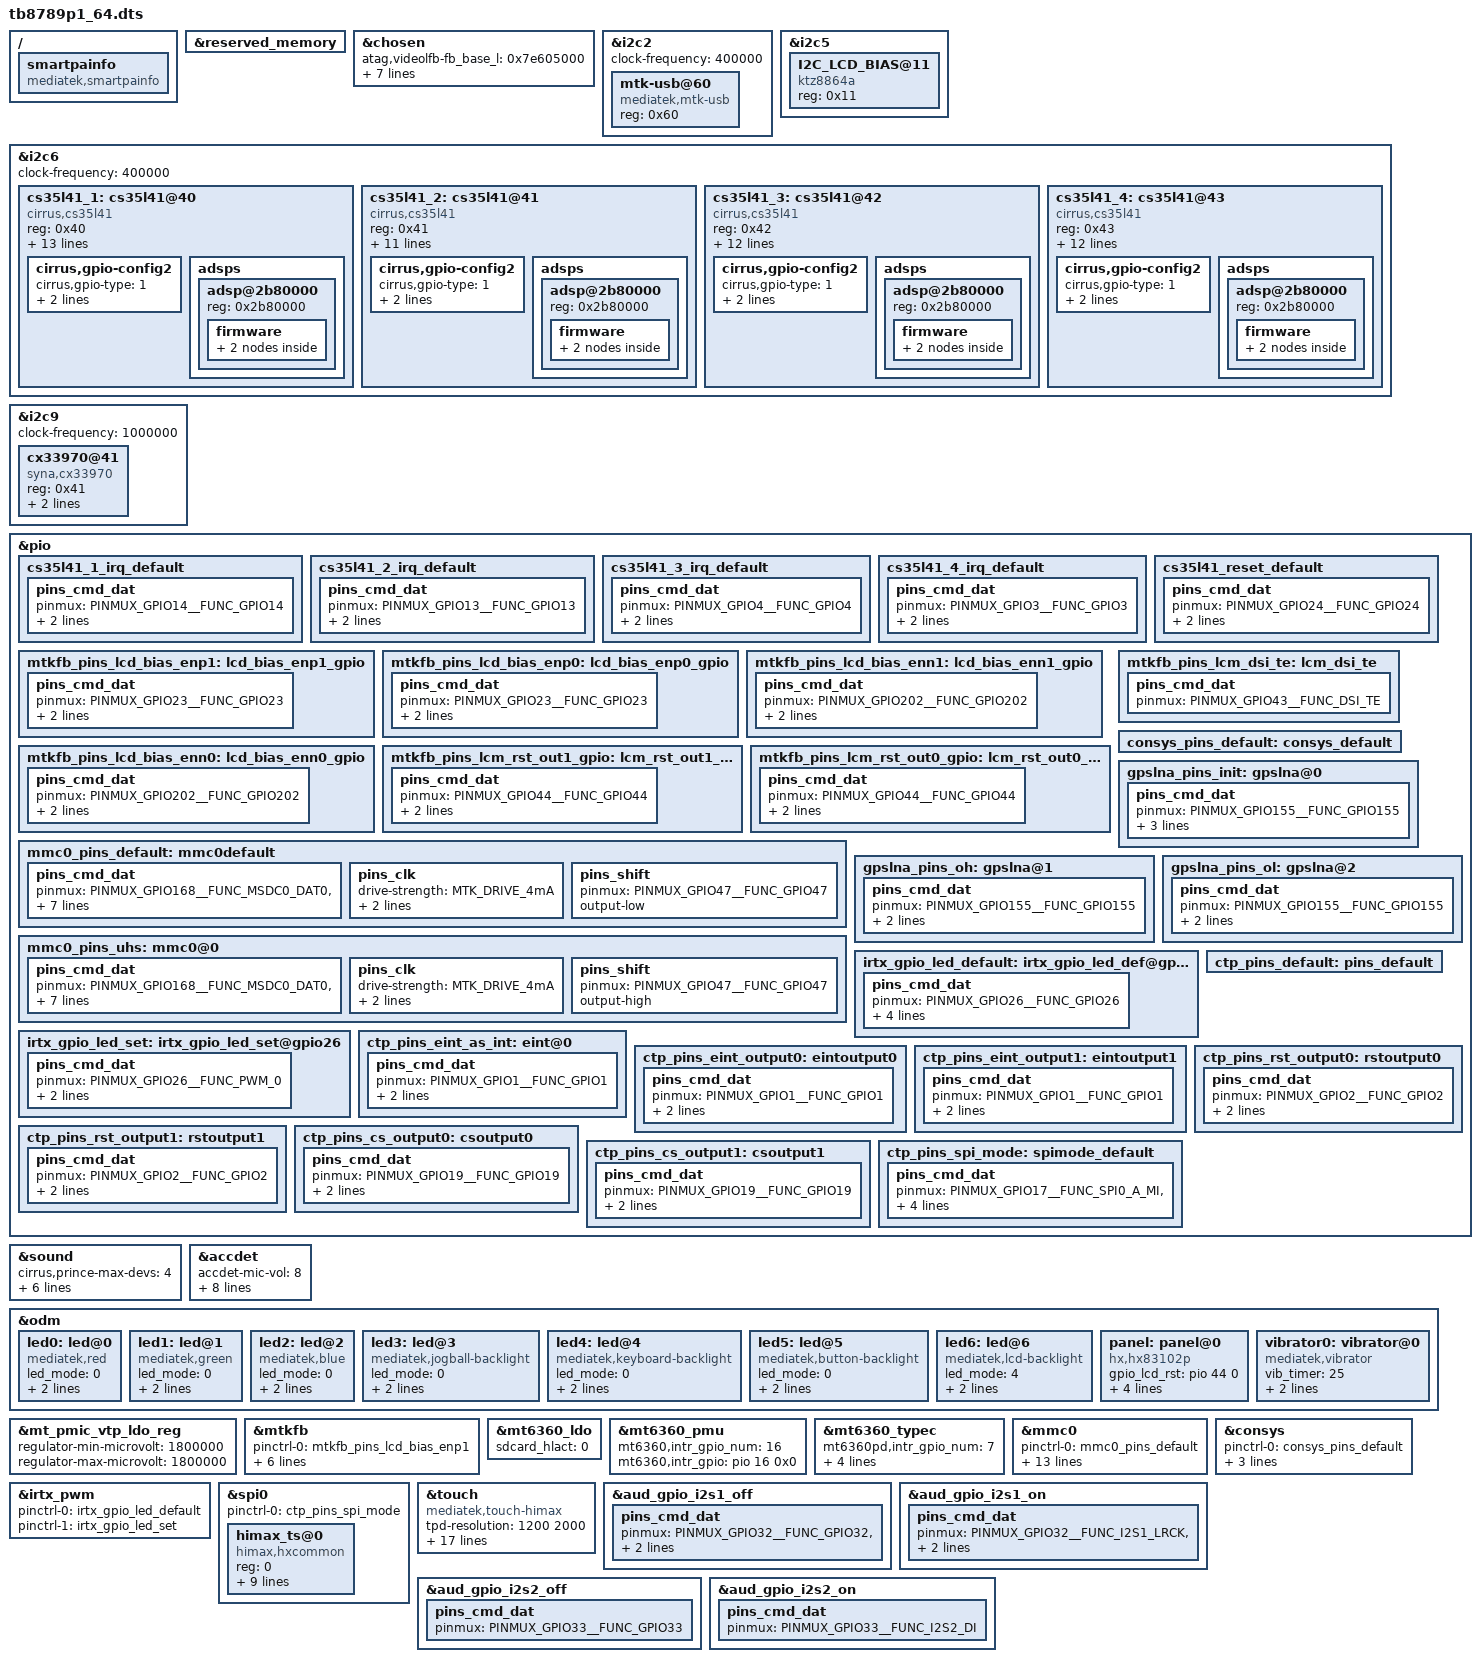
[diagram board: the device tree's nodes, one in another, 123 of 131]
/*
 * Copyright (C) 2015 MediaTek Inc.
 *
 * This program is free software: you can redistribute it and/or modify
 * it under the terms of the GNU General Public License version 2 as
 * published by the Free Software Foundation.
 *
 * This program is distributed in the hope that it will be useful,
 * but WITHOUT ANY WARRANTY; without even the implied warranty of
 * MERCHANTABILITY or FITNESS FOR A PARTICULAR PURPOSE. See the
 * GNU General Public License for more details.
 */
/dts-v1/;
/plugin/;
#include <dt-bindings/interrupt-controller/irq.h>
#include <dt-bindings/interrupt-controller/arm-gic.h>
#include <dt-bindings/pinctrl/mt6785-pinfunc.h>

/ {
	smartpainfo: smartpainfo {
		compatible = "mediatek,smartpainfo";
	};
};

&reserved_memory {
};

/* chosen */
&chosen {
	/* fpga may has no lk, we need to specify display info here */
	/* fb buffer is reserved using this dts by memory node above */

	atag,videolfb-fb_base_l = <0x7e605000>;
	atag,videolfb-fb_base_h = <0x0>;
	atag,videolfb-islcmfound = <1>;
	atag,videolfb-islcm_inited = <0>;
	atag,videolfb-fps= <6000>;
	atag,videolfb-vramSize= <0x017e8000>;
	atag,videolfb-lcmname=
		"hx83102p_wuxga2000_dsi_vdo_boe_drv";
};


&i2c2 {
	clock-frequency = <400000>;

	mtk-usb@60 {
		compatible = "mediatek,mtk-usb";
		reg = <0x60>;
		status = "okay";
	};
};

&i2c5 {
	I2C_LCD_BIAS@11 {
		compatible = "ktz8864a" ;
		reg = <0x11> ;
		status = "okay" ;
	};
};

&i2c6 {
	clock-frequency = <400000>;

	status="okay";

	/* Speaker 1st Amp */
	/*U2401  ---->  40*/
	cs35l41_1: cs35l41@40 {
		compatible = "cirrus,cs35l41";
		reg = <0x40>;

		reset-gpios = <&pio 24 0>;
		interrupt-parent = <&pio>;
		interrupts = <14 IRQ_TYPE_LEVEL_LOW 14 0>;
		interrupt-controller;
		#interrupt-cells = <2>;
		interrupt-names = "cs35l41_1_irq";

		pinctrl-names="default";
		pinctrl-0=<&cs35l41_1_irq_default>, <&cs35l41_reset_default>;


		cirrus,boost-peak-milliamp = <4500>;
		cirrus,boost-ind-nanohenry = <1000>;
		cirrus,boost-cap-microfarad = <15>;
		cirrus,asp-sdout-hiz = <0x3>;
		cirrus,fast-switch = "spk1_fast_switch1.txt", "spk1_fast_switch2.txt",
							"spk1_fast_switch3.txt",
							"spk1_fast_switch4.txt";

		cirrus,gpio-config2 {
			cirrus,gpio-type = <1>; /* 0 indicate gpio, 1 indicate interrupt */
			cirrus,gpio-src-select = <0x4>;
			cirrus,gpio-output-enable;
		};
		adsps {
			#address-cells = <1>;
			#size-cells = <0>;
			adsp@2b80000 {
				reg = <0x2b80000>;
				firmware {
					protection {
						cirrus,full-name;
						cirrus,wmfw-file = "cs35l41-dsp1-spk-prot.wmfw";
						cirrus,bin-file = "cs35l41-dsp1-spk-prot1.bin";
					};
					calibration {
						cirrus,full-name;
						cirrus,wmfw-file = "cs35l41-dsp1-spk-cali.wmfw";
						cirrus,bin-file = "cs35l41-dsp1-spk-cali.bin";
					};
				};
			};
		};
	};

	/* Speaker 2nd Amp */
	/*U2404 --->  41*/
	cs35l41_2: cs35l41@41 {
		compatible = "cirrus,cs35l41";
		reg = <0x41>;

		//reset-gpios = <&pio 24 0>;
		interrupt-parent = <&pio>;
		interrupts = <13 IRQ_TYPE_LEVEL_LOW 13 0>;
		interrupt-controller;
		#interrupt-cells = <2>;
		interrupt-names = "cs35l41_2_irq";

		pinctrl-names="default";
		pinctrl-0=<&cs35l41_2_irq_default>;

		cirrus,boost-peak-milliamp = <4500>;
		cirrus,boost-ind-nanohenry = <1000>;
		cirrus,boost-cap-microfarad = <15>;
		cirrus,asp-sdout-hiz = <0x3>;
		cirrus,fast-switch = "spk2_fast_switch1.txt", "spk2_fast_switch2.txt",
							"spk2_fast_switch3.txt",
							"spk2_fast_switch4.txt";

		cirrus,gpio-config2 {
			cirrus,gpio-type = <1>; /* 0 indicate gpio, 1 indicate interrupt */
			cirrus,gpio-src-select = <0x4>;
			cirrus,gpio-output-enable;
		};
		adsps {
			#address-cells = <1>;
			#size-cells = <0>;
			adsp@2b80000 {
				reg = <0x2b80000>;
				firmware {
					protection {
						cirrus,full-name;
						cirrus,wmfw-file = "cs35l41-dsp1-spk-prot.wmfw";
						cirrus,bin-file = "cs35l41-dsp1-spk-prot2.bin";
					};
					calibration {
						cirrus,full-name;
						cirrus,wmfw-file = "cs35l41-dsp1-spk-cali.wmfw";
						cirrus,bin-file = "cs35l41-dsp1-spk-cali.bin";
					};
				};
			};
		};
	};

	/* Speaker 3rd Amp */
	/*u2402 ----->  42*/
	cs35l41_3: cs35l41@42 {
		compatible = "cirrus,cs35l41";
		reg = <0x42>;

		//reset-gpios = <&pio 24 0>;
		interrupt-parent = <&pio>;
		interrupts = <4 IRQ_TYPE_LEVEL_LOW 4 0>;
		interrupt-controller;
		#interrupt-cells = <2>;
		interrupt-names = "cs35l41_3_irq";

		pinctrl-names="default";
		pinctrl-0=<&cs35l41_3_irq_default>;
		cirrus,boost-peak-milliamp = <4500>;
		cirrus,boost-ind-nanohenry = <1000>;
		cirrus,boost-cap-microfarad = <15>;
		cirrus,asp-sdout-hiz = <0x3>;
		cirrus,right-channel-amp;
		cirrus,fast-switch = "spk3_fast_switch1.txt", "spk3_fast_switch2.txt",
							"spk3_fast_switch3.txt",
							"spk3_fast_switch4.txt";

		cirrus,gpio-config2 {
			cirrus,gpio-type = <1>; /* 0 indicate gpio, 1 indicate interrupt */
			cirrus,gpio-src-select = <0x4>;
			cirrus,gpio-output-enable;
		};
		adsps {
			#address-cells = <1>;
			#size-cells = <0>;
			adsp@2b80000 {
				reg = <0x2b80000>;
				firmware {
					protection {
						cirrus,full-name;
						cirrus,wmfw-file = "cs35l41-dsp1-spk-prot.wmfw";
						cirrus,bin-file = "cs35l41-dsp1-spk-prot3.bin";
					};
					calibration {
						cirrus,full-name;
						cirrus,wmfw-file = "cs35l41-dsp1-spk-cali.wmfw";
						cirrus,bin-file = "cs35l41-dsp1-spk-cali.bin";
					};
				};
			};
		};
	};

	/* Speaker 4th Amp */
	/*U2403  ---->  43*/
	cs35l41_4: cs35l41@43 {
		compatible = "cirrus,cs35l41";
		reg = <0x43>;

		//reset-gpios = <&pio 24 0>;
		interrupt-parent = <&pio>;
		interrupts = <3 IRQ_TYPE_LEVEL_LOW 3 0>;
		interrupt-controller;
		#interrupt-cells = <2>;
		interrupt-names = "cs35l41_4_irq";

		pinctrl-names="default";
		pinctrl-0=<&cs35l41_4_irq_default>;
		cirrus,boost-peak-milliamp = <4500>;
		cirrus,boost-ind-nanohenry = <1000>;
		cirrus,boost-cap-microfarad = <15>;
		cirrus,asp-sdout-hiz = <0x3>;
		cirrus,right-channel-amp;
		cirrus,fast-switch = "spk4_fast_switch1.txt", "spk4_fast_switch2.txt",
							"spk4_fast_switch3.txt",
							"spk4_fast_switch4.txt";

		cirrus,gpio-config2 {
			cirrus,gpio-type = <1>; /* 0 indicate gpio, 1 indicate interrupt */
			cirrus,gpio-src-select = <0x4>;
			cirrus,gpio-output-enable;
		};
		adsps {
			#address-cells = <1>;
			#size-cells = <0>;
			adsp@2b80000 {
				reg = <0x2b80000>;
				firmware {
					protection {
						cirrus,full-name;
						cirrus,wmfw-file = "cs35l41-dsp1-spk-prot.wmfw";
						cirrus,bin-file = "cs35l41-dsp1-spk-prot4.bin";
					};
					calibration {
						cirrus,full-name;
						cirrus,wmfw-file = "cs35l41-dsp1-spk-cali.wmfw";
						cirrus,bin-file = "cs35l41-dsp1-spk-cali.bin";
					};
				};
			};
		};
	};
};

&i2c9 {
	clock-frequency = <1000000>;
	cx33970@41 {
		compatible = "syna,cx33970";
		reg = <0x41>;
		reset-gpios = <&pio 122 0x0>;
		enable-gpio = <&pio 49 0x0>;
		status = "okay";
	};
};

&pio {
	cs35l41_1_irq_default: cs35l41_1_irq_default {
		pins_cmd_dat {
			pinmux = <PINMUX_GPIO14__FUNC_GPIO14>;
			slew-rate = <0>;
			bias-pull-up = <00>;
		};
	};

	cs35l41_2_irq_default: cs35l41_2_irq_default {
		pins_cmd_dat {
			pinmux = <PINMUX_GPIO13__FUNC_GPIO13>;
			slew-rate = <0>;
			bias-pull-up = <00>;
		};
	};

	cs35l41_3_irq_default: cs35l41_3_irq_default {
		pins_cmd_dat {
			pinmux = <PINMUX_GPIO4__FUNC_GPIO4>;
			slew-rate = <0>;
			bias-pull-up = <00>;
		};
	};

	cs35l41_4_irq_default: cs35l41_4_irq_default {
		pins_cmd_dat {
			pinmux = <PINMUX_GPIO3__FUNC_GPIO3>;
			slew-rate = <0>;
			bias-pull-up = <00>;
		};
	};

	cs35l41_reset_default: cs35l41_reset_default {
		pins_cmd_dat {
			pinmux = <PINMUX_GPIO24__FUNC_GPIO24>;
			slew-rate = <1>;
			bias-pull-up = <00>;
		};
	};
};

&sound{
	cirrus,prince-max-devs = <4>;
	cirrus,prince-devs = <&cs35l41_1>, <&cs35l41_2>, <&cs35l41_3>, <&cs35l41_4>;
	cirrus,prince-dev-prefix = "SPK1", "SPK2", "SPK3", "SPK4";
	mtk_spk_i2s_out = <1>;
	mtk_spk_i2s_in = <2>;
};


/* accdet start */
&accdet {
	/* accdet micbias voltage: 0x09:2.85v 0x08:2.8v 0x07,
	 * 2.7v;0x05,2.5v;0x02,1.9v
	 */
	accdet-mic-vol = <8>;
	/* accdet pwm_width, pwm_thresh, fall_delay, rise_delay
	 * debounce0, debounce1, debounce3, debounce4
	 * eint pwm_width, eint pwm_thresh
	 * eint deb(debounce0, debounce1, debounce2, debounce3), inv_debounce
	 */
	headset-mode-setting = <0x500 0x500 1 0x1f0
				0x800 0x800 0x20 0x44
				0x4 0x1
				0x5 0x3 0x3 0x5 0xe>;
	accdet-plugout-debounce = <1>;
	/*1:ACC mode, 2:low cost without in bias, 6:low cost with in bias*/
	accdet-mic-mode = <2>;
	/*0--MD_MAX--UP_MAX--DW_MAX*/
	headset-three-key-threshold = <0 80 220 400>;
	headset-three-key-threshold-CDD = <0 121 192 600>;
	/*0--MD_MAX--VOICE_MAX--UP_MAX--DW_MAX*/
	headset-four-key-threshold = <0 58 121 192 400>;

	/* select VTH to 2v and 500k, use internal resitance */
	eint_use_ext_res = <0>;
	status = "okay";
};
/* accdet end */

&odm {
	led0:led@0 {
		compatible = "mediatek,red";
		led_mode = <0>;
		data = <1>;
		pwm_config = <0 0 0 0 0>;
	};
	led1:led@1 {
		compatible = "mediatek,green";
		led_mode = <0>;
		data = <1>;
		pwm_config = <0 0 0 0 0>;
	};
	led2:led@2 {
		compatible = "mediatek,blue";
		led_mode = <0>;
		data = <1>;
		pwm_config = <0 0 0 0 0>;
	};
	led3:led@3 {
		compatible = "mediatek,jogball-backlight";
		led_mode = <0>;
		data = <1>;
		pwm_config = <0 0 0 0 0>;
	};
	led4:led@4 {
		compatible = "mediatek,keyboard-backlight";
		led_mode = <0>;
		data = <1>;
		pwm_config = <0 0 0 0 0>;
	};
	led5:led@5 {
		compatible = "mediatek,button-backlight";
		led_mode = <0>;
		data = <1>;
		pwm_config = <0 0 0 0 0>;
	};
	led6:led@6 {
		compatible = "mediatek,lcd-backlight";
		led_mode = <4>;
		data = <1>;
		pwm_config = <0 1 0 0 0>;
	};

	panel: panel@0 {
		compatible = "hx,hx83102p";
		gpio_lcd_rst = <&pio 44 0>;
		gpio_lcd_bl_en = <&pio 22 0>;
		gpio_lcd_bias_enp = <&pio 23 0>;
		gpio_lcd_bias_enn = <&pio 202 0>;
		reg-lcm-supply = <&mt_pmic_vtp_ldo_reg>;
		status = "okay";
	};

	vibrator0:vibrator@0 {
		compatible = "mediatek,vibrator";
		vib_timer = <25>;
		vib_limit = <9>;
		vib_vol= <9>;
	};

};

/* DISPSYS GPIO standardization */
&pio {
	mtkfb_pins_lcd_bias_enp1: lcd_bias_enp1_gpio {
		pins_cmd_dat {
			pinmux = <PINMUX_GPIO23__FUNC_GPIO23>;
			slew-rate = <1>;
			output-high;
		};
	};

	mtkfb_pins_lcd_bias_enp0: lcd_bias_enp0_gpio {
		pins_cmd_dat {
			pinmux = <PINMUX_GPIO23__FUNC_GPIO23>;
			slew-rate = <1>;
			output-low;
		};
	};

	mtkfb_pins_lcd_bias_enn1: lcd_bias_enn1_gpio {
		pins_cmd_dat {
			pinmux = <PINMUX_GPIO202__FUNC_GPIO202>;
			slew-rate = <1>;
			output-high;
		};
	};

	mtkfb_pins_lcd_bias_enn0: lcd_bias_enn0_gpio {
		pins_cmd_dat {
			pinmux = <PINMUX_GPIO202__FUNC_GPIO202>;
			slew-rate = <1>;
			output-low;
		};
	};

	mtkfb_pins_lcm_rst_out1_gpio: lcm_rst_out1_gpio {
		pins_cmd_dat {
			pinmux = <PINMUX_GPIO44__FUNC_GPIO44>;
			slew-rate = <1>;
			output-high;
		};
	};

	mtkfb_pins_lcm_rst_out0_gpio: lcm_rst_out0_gpio {
		pins_cmd_dat {
			pinmux = <PINMUX_GPIO44__FUNC_GPIO44>;
			slew-rate = <1>;
			output-low;
		};
	};
	mtkfb_pins_lcm_dsi_te: lcm_dsi_te {
		pins_cmd_dat {
			pinmux = <PINMUX_GPIO43__FUNC_DSI_TE>;
		};
	};
};

&mt_pmic_vtp_ldo_reg {
	regulator-min-microvolt = <1800000>;
	regulator-max-microvolt = <1800000>;
};

&mtkfb {
	pinctrl-names = "lcd_bias_enp1_gpio", "lcd_bias_enp0_gpio",
		"lcd_bias_enn1_gpio", "lcd_bias_enn0_gpio",
		"lcm_rst_out1_gpio", "lcm_rst_out0_gpio",
		"mode_te_te";
	pinctrl-0 = <&mtkfb_pins_lcd_bias_enp1>;
	pinctrl-1 = <&mtkfb_pins_lcd_bias_enp0>;
	pinctrl-2 = <&mtkfb_pins_lcd_bias_enn1>;
	pinctrl-3 = <&mtkfb_pins_lcd_bias_enn0>;
	pinctrl-4 = <&mtkfb_pins_lcm_rst_out1_gpio>;
	pinctrl-5 = <&mtkfb_pins_lcm_rst_out0_gpio>;
	pinctrl-6 = <&mtkfb_pins_lcm_dsi_te>;
	status = "okay";
};

/* DISPSYS GPIO standardization end */
&mt6360_ldo {
	sdcard_hlact = <0>;
};

&mt6360_pmu {
	mt6360,intr_gpio_num = <16>; /* direct defined GPIO num */
	mt6360,intr_gpio = <&pio 16 0x0>;
};

&mt6360_typec {
	mt6360pd,intr_gpio_num = <7>; /* direct defined GPIO num */
	mt6360pd,intr_gpio = <&pio 7 0x0>;
	mt6360pd,pcb_gpio = <&pio 5 0x0>;
	mt6360pd,pcb_gpio_num = <5>;
	mt6360pd,pcb_gpio_polarity = <1>;
};

/* USB SWITCH GPIO start */
&pio {
	mmc0_pins_default: mmc0default {
		   pins_cmd_dat {
			   pinmux = <PINMUX_GPIO168__FUNC_MSDC0_DAT0>,
				  <PINMUX_GPIO172__FUNC_MSDC0_DAT1>,
				  <PINMUX_GPIO169__FUNC_MSDC0_DAT2>,
				  <PINMUX_GPIO177__FUNC_MSDC0_DAT3>,
				  <PINMUX_GPIO167__FUNC_MSDC0_CMD>;
			   drive-strength = <MTK_DRIVE_4mA>;
			   input-enable;
			   bias-pull-up = <MTK_PUPD_SET_R1R0_01>;
		   };

		   pins_clk {
			   drive-strength = <MTK_DRIVE_4mA>;
			   pinmux = <PINMUX_GPIO176__FUNC_MSDC0_CLK>;
			   bias-pull-down = <MTK_PUPD_SET_R1R0_10>;
		   };

		   pins_shift {
			   pinmux = <PINMUX_GPIO47__FUNC_GPIO47>;
			   output-low;
		   };
	};

	mmc0_pins_uhs: mmc0@0 {
		   pins_cmd_dat {
			   pinmux = <PINMUX_GPIO168__FUNC_MSDC0_DAT0>,
				  <PINMUX_GPIO172__FUNC_MSDC0_DAT1>,
				  <PINMUX_GPIO169__FUNC_MSDC0_DAT2>,
				  <PINMUX_GPIO177__FUNC_MSDC0_DAT3>,
				  <PINMUX_GPIO167__FUNC_MSDC0_CMD>;
			   drive-strength = <MTK_DRIVE_4mA>;
			   input-enable;
			   bias-pull-up = <MTK_PUPD_SET_R1R0_01>;
		   };

		   pins_clk {
			   drive-strength = <MTK_DRIVE_4mA>;
			   pinmux = <PINMUX_GPIO176__FUNC_MSDC0_CLK>;
			   bias-pull-down = <MTK_PUPD_SET_R1R0_10>;
		   };

		   pins_shift {
			   pinmux = <PINMUX_GPIO47__FUNC_GPIO47>;
			   output-high;
		   };
	};

};

&mmc0 {
	pinctrl-names = "default", "state_uhs";
	pinctrl-0 = <&mmc0_pins_default>;
	pinctrl-1 = <&mmc0_pins_uhs>;
	status = "okay";
	bus-width = <4>;
	max-frequency = <200000000>;
	cd-gpios = <&pio 8 0>;
	cap-sd-highspeed;
	sd-uhs-sdr12;
	sd-uhs-sdr25;
	sd-uhs-sdr50;
	sd-uhs-sdr104;
	no-sdio;
	no-mmc;
	vmmc-supply = <&mt_pmic_vmch_ldo_reg>;
	vqmmc-supply = <&mt_pmic_vmc_ldo_reg>;
};

/* CONSYS GPIO standardization */
&pio {
	consys_pins_default: consys_default {
	};
	gpslna_pins_init: gpslna@0 {
		pins_cmd_dat {
			pinmux = <PINMUX_GPIO155__FUNC_GPIO155>;
			slew-rate = <0>;
			bias-disable;
			output-low;
		};
	};
	gpslna_pins_oh: gpslna@1 {
		pins_cmd_dat {
			pinmux = <PINMUX_GPIO155__FUNC_GPIO155>;
			slew-rate = <1>;
			output-high;
		};
	};
	gpslna_pins_ol: gpslna@2 {
		pins_cmd_dat {
			pinmux = <PINMUX_GPIO155__FUNC_GPIO155>;
			slew-rate = <1>;
			output-low;
		};
	};
};
&consys {
	pinctrl-names = "default", "gps_lna_state_init",
		"gps_lna_state_oh", "gps_lna_state_ol";
	pinctrl-0 = <&consys_pins_default>;
	pinctrl-1 = <&gpslna_pins_init>;
	pinctrl-2 = <&gpslna_pins_oh>;
	pinctrl-3 = <&gpslna_pins_ol>;
	status = "okay";
};
/* CONSYS end */

/* IRTX GPIO Start */
&irtx_pwm {
	pinctrl-names = "irtx_gpio_led_default", "irtx_gpio_led_set";
	pinctrl-0 = <&irtx_gpio_led_default>;
	pinctrl-1 = <&irtx_gpio_led_set>;
	status = "okay";
};
&pio {
	/* IRTX GPIO Settings -Start */
	/* default: GPIO0, output, high */
	irtx_gpio_led_default:irtx_gpio_led_def@gpio26 {
		pins_cmd_dat {
			pinmux = <PINMUX_GPIO26__FUNC_GPIO26>;
			slew-rate = <1>;
			bias-disable;
			output-low;
			input-schmitt-enable = <0>;
		};
	};

	irtx_gpio_led_set:irtx_gpio_led_set@gpio26 {
		pins_cmd_dat {
			pinmux = <PINMUX_GPIO26__FUNC_PWM_0>;
			slew-rate = <1>;
			output-high;
		};
	};
}; /* IRTX GPIO Settings -End */

/* TOUCH start */
&pio {
	ctp_pins_default: pins_default {
	};
	ctp_pins_eint_as_int: eint@0 {
		pins_cmd_dat {
			pinmux = <PINMUX_GPIO1__FUNC_GPIO1>;
			slew-rate = <0>;
			bias-disable;
		};
	};
	ctp_pins_eint_output0: eintoutput0 {
		pins_cmd_dat {
			pinmux = <PINMUX_GPIO1__FUNC_GPIO1>;
			slew-rate = <1>;
			output-low;
		};
	};
	ctp_pins_eint_output1: eintoutput1 {
		pins_cmd_dat {
			pinmux = <PINMUX_GPIO1__FUNC_GPIO1>;
			slew-rate = <1>;
			output-high;
		};
	};
	ctp_pins_rst_output0: rstoutput0 {
		pins_cmd_dat {
			pinmux = <PINMUX_GPIO2__FUNC_GPIO2>;
			slew-rate = <1>;
			output-low;
		};
	};
	ctp_pins_rst_output1: rstoutput1 {
		pins_cmd_dat {
			pinmux = <PINMUX_GPIO2__FUNC_GPIO2>;
			slew-rate = <1>;
			output-high;
		};
	};
	ctp_pins_cs_output0: csoutput0 {
		pins_cmd_dat {
			pinmux = <PINMUX_GPIO19__FUNC_GPIO19>;
			slew-rate = <1>;
			output-low;
		};
	};
	ctp_pins_cs_output1: csoutput1 {
		pins_cmd_dat {
			pinmux = <PINMUX_GPIO19__FUNC_GPIO19>;
			slew-rate = <1>;
			output-high;
		};
	};
	ctp_pins_spi_mode: spimode_default {
		pins_cmd_dat {
			pinmux = <PINMUX_GPIO17__FUNC_SPI0_A_MI>,
				<PINMUX_GPIO18__FUNC_SPI0_A_MO>,
				<PINMUX_GPIO19__FUNC_SPI0_A_CSB>,
				<PINMUX_GPIO20__FUNC_SPI0_A_CLK>;
			drive-strength=<4>;
		};
	};
};

&spi0 {
	status = "okay";
	pinctrl-names = "default";
	pinctrl-0 = <&ctp_pins_spi_mode>;
	himax_ts@0 {
		compatible = "himax,hxcommon";
		reg = <0>;
		spi-max-frequency = <10000000>;
		spi-cpha = <1>;
		spi-cpol = <1>;
		interrupt-parent = <&pio>;
		himax,panel-coords = <0 1200 0 2000>;
		himax,display-cords = <0 1200 0 2000>;
		himax,irq-gpio = <&pio 1 0>;
		himax,rst-gpio = <&pio 2 0>;
		report_type = <1>;
	};
};

&touch {
	compatible = "mediatek,touch-himax";
	tpd-resolution = <1200 2000>;
	use-tpd-button = <0>;
	tpd-key-num = <10>;
	tpd-key-local= <139 172 158 0>;
	tpd-key-dim-local = <60 850 50 30
		180 850 50 30 300 850 50 30 420 850 50 30>;
	tpd-max-touch-num = <5>;
	tpd-filter-enable = <1>;
	tpd-filter-pixel-density = <124>;
	tpd-filter-custom-prameters = <0 0 0 0 0 0 0 0 0 0 0 0>;
	tpd-filter-custom-speed = <0 0 0>;
	pinctrl-names = "default", "state_eint_as_int", "state_eint_output0",
		"state_eint_output1", "state_rst_output0", "state_rst_output1";
	pinctrl-0 = <&ctp_pins_default>;
	pinctrl-1 = <&ctp_pins_eint_as_int>;
	pinctrl-2 = <&ctp_pins_eint_output0>;
	pinctrl-3 = <&ctp_pins_eint_output1>;
	pinctrl-4 = <&ctp_pins_rst_output0>;
	pinctrl-5 = <&ctp_pins_rst_output1>;
	status = "okay";
};

&aud_gpio_i2s1_off {
	pins_cmd_dat {
		pinmux = <PINMUX_GPIO32__FUNC_GPIO32>,
			 <PINMUX_GPIO34__FUNC_GPIO34>,
			 <PINMUX_GPIO31__FUNC_GPIO31>;
	};
};

&aud_gpio_i2s1_on {
	pins_cmd_dat {
		pinmux = <PINMUX_GPIO32__FUNC_I2S1_LRCK>,
			 <PINMUX_GPIO34__FUNC_I2S1_DO>,
			 <PINMUX_GPIO31__FUNC_I2S1_BCK>;
	};
};

&aud_gpio_i2s2_off {
	pins_cmd_dat {
		pinmux = <PINMUX_GPIO33__FUNC_GPIO33>;
	};
};

&aud_gpio_i2s2_on {
	pins_cmd_dat {
		pinmux = <PINMUX_GPIO33__FUNC_I2S2_DI>;
	};
};

#include <tb8789p1_64/cust.dtsi>
#include "mediatek/cust_mt6785_camera_8789p1.dtsi"
/*End of this file, DO NOT ADD ANYTHING HERE*/
